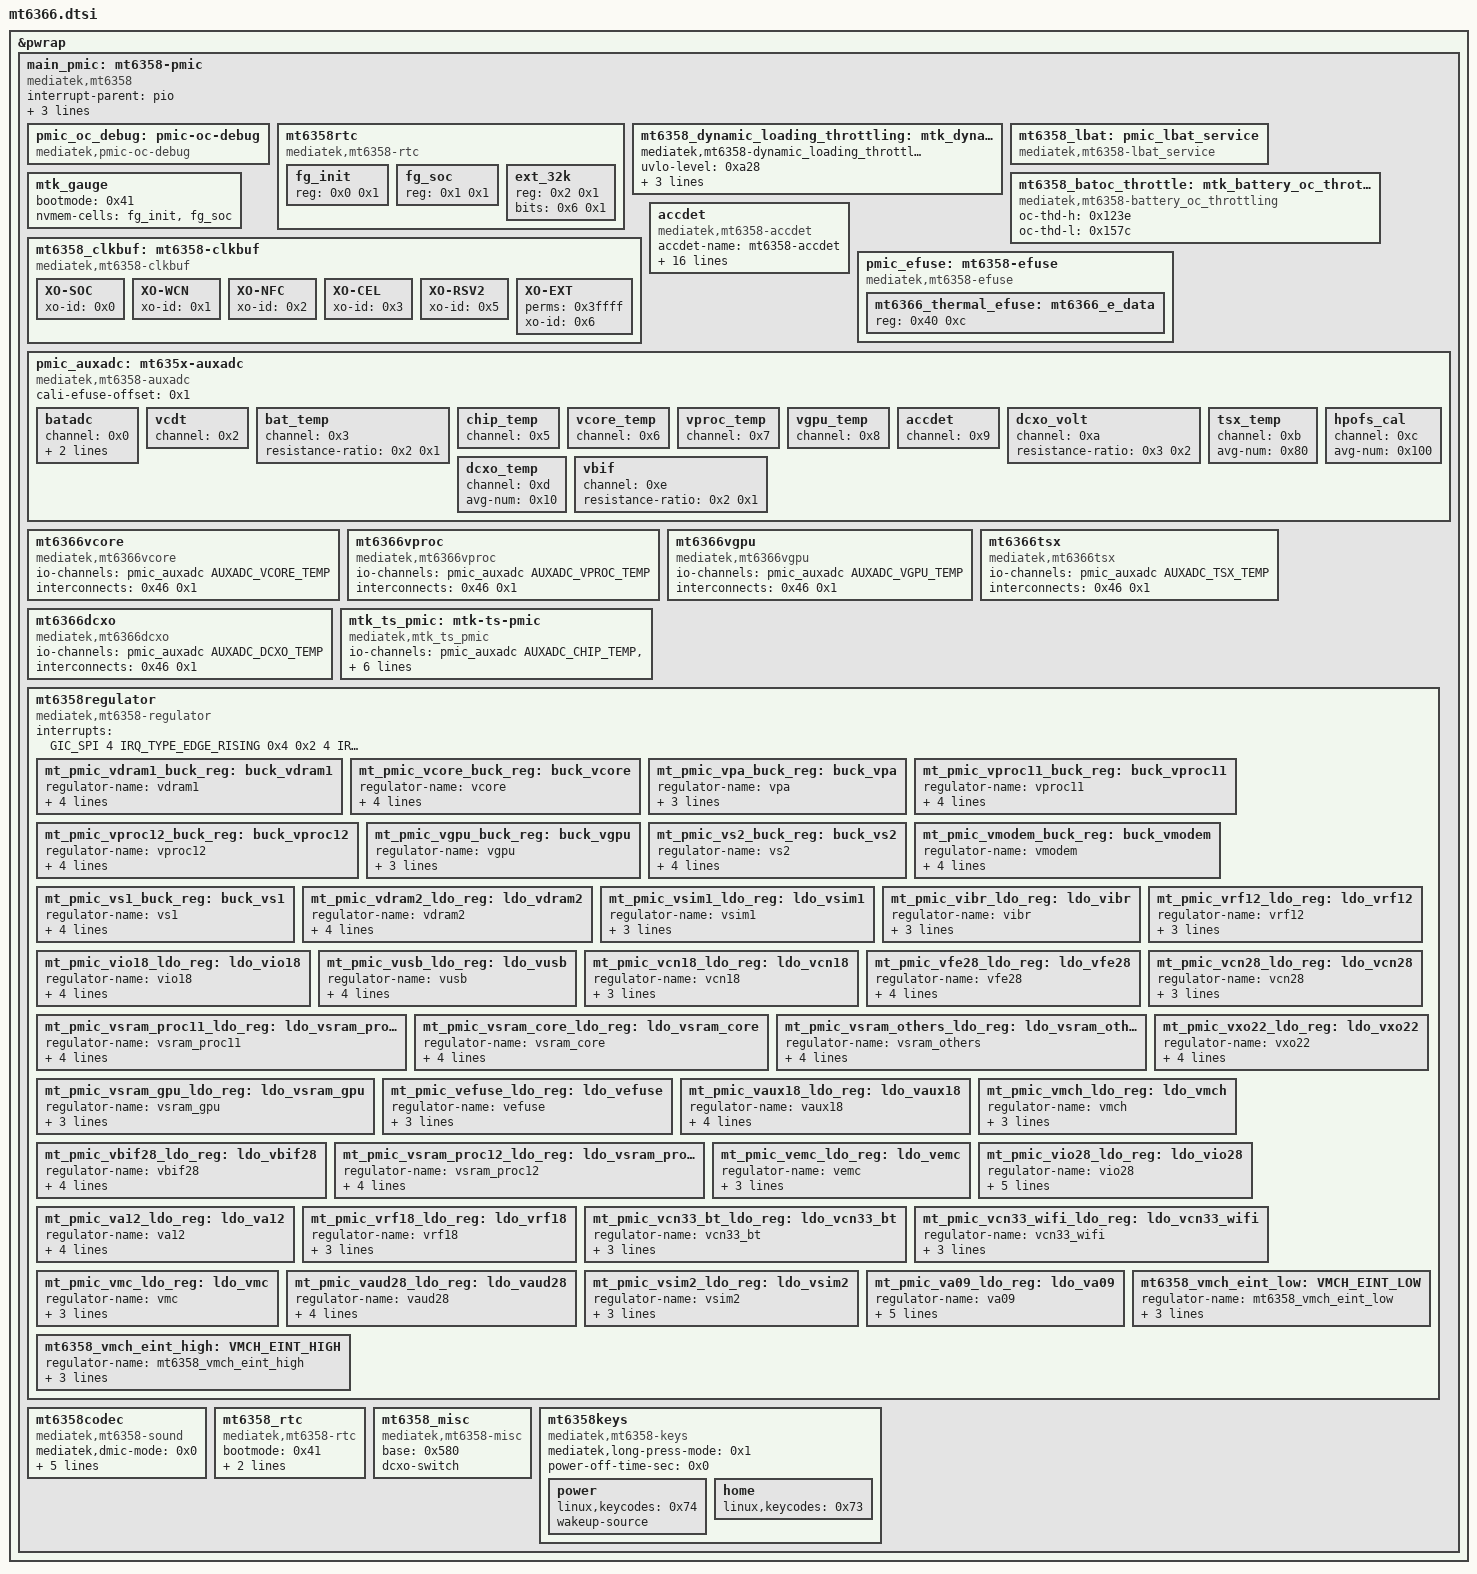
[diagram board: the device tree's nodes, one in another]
// SPDX-License-Identifier: GPL-2.0-only
/* MediaTek MT6358 / MT6366 PMIC MFD, Regulators, AuxADC, RTC, Keys & Gauge bindings for Kernel 6.6 */

&pwrap {
    main_pmic: mt6358-pmic {
        compatible = "mediatek,mt6358";
        interrupt-parent = <&pio>;
        interrupts = <0x90 0x4 0x90 0x0>;
        status = "okay";
        interrupt-controller;
        #interrupt-cells = <0x2>;
        mediatek,num-pmic-irqs = <0x91>;
        pmic_oc_debug: pmic-oc-debug {
            compatible = "mediatek,pmic-oc-debug";
        };
        mt6358rtc: mt6358rtc {
            compatible = "mediatek,mt6358-rtc";
            #address-cells = <0x1>;
            #size-cells = <0x1>;
            fg_init: fg_init {
                reg = <0x0 0x1>;
            };
            fg_soc: fg_soc {
                reg = <0x1 0x1>;
            };
            ext_32k: ext_32k {
                reg = <0x2 0x1>;
                bits = <0x6 0x1>;
            };
        };
        mt6358_dynamic_loading_throttling: mtk_dynamic_loading_throttling {
            compatible = "mediatek,mt6358-dynamic_loading_throttling";
            uvlo-level = <0xa28>;
            io-channels = <&pmic_auxadc AUXADC_IMP &pmic_auxadc AUXADC_IMIX_R &pmic_auxadc AUXADC_BATADC>;
            io-channel-names = "pmic_ptim", "pmic_imix_r", "pmic_batadc";
        };
        mt6358_lbat: pmic_lbat_service {
            compatible = "mediatek,mt6358-lbat_service";
        };
        mt6358_batoc_throttle: mtk_battery_oc_throttling {
            compatible = "mediatek,mt6358-battery_oc_throttling";
            oc-thd-h = <0x123e>;
            oc-thd-l = <0x157c>;
        };
        mtk_gauge: mtk_gauge {
            bootmode = <0x41>;
            nvmem-cells = <&fg_init &fg_soc>;
        };
        mt6358_clkbuf: mt6358-clkbuf {
            compatible = "mediatek,mt6358-clkbuf";
            XO-SOC {
                xo-id = <0x0>;
            };
            XO-WCN {
                xo-id = <0x1>;
            };
            XO-NFC {
                xo-id = <0x2>;
            };
            XO-CEL {
                xo-id = <0x3>;
            };
            XO-RSV2 {
                xo-id = <0x5>;
            };
            XO-EXT {
                perms = <0x3ffff>;
                xo-id = <0x6>;
            };
        };
        accdet: accdet {
            compatible = "mediatek,mt6358-accdet";
            accdet-name = "mt6358-accdet";
            mediatek,accdet-pmic = <0x66>;
            accdet-mic-vol = <0x6>;
            headset-mode-setting = <0x500 0x500 0x1 0x1f0 0x800 0x800 0x20 0x44 0x0 0x0 0xe 0x0 0x0 0x0 0x0>;
            accdet-plugout-debounce = <0x1>;
            accdet-mic-mode = <0x1>;
            headset-eint-level-pol = <0x8>;
            headset-three-key-threshold = <0x0 0x50 0xdc 0x190>;
            headset-three-key-threshold-CDD = <0x0 0x79 0xc0 0x258>;
            headset-four-key-threshold = <0x0 0x3a 0x79 0xc0 0x190>;
            io-channels = <&pmic_auxadc AUXADC_ACCDET>;
            io-channel-names = "pmic_accdet";
            nvmem = <&pmic_efuse>;
            nvmem-names = "mt63xx-accdet-efuse";
            status = "okay";
        };
        pmic_efuse: mt6358-efuse {
            compatible = "mediatek,mt6358-efuse";
            #address-cells = <0x1>;
            #size-cells = <0x1>;
            mt6366_thermal_efuse: mt6366_e_data {
                reg = <0x40 0xc>;
            };
        };
        pmic_auxadc: mt635x-auxadc {
            compatible = "mediatek,mt6358-auxadc";
            #io-channel-cells = <0x1>;
            cali-efuse-offset = <0x1>;
            batadc {
                channel = <0x0>;
                resistance-ratio = <0x3 0x1>;
                avg-num = <0x80>;
            };
            vcdt {
                channel = <0x2>;
            };
            bat_temp {
                channel = <0x3>;
                resistance-ratio = <0x2 0x1>;
            };
            chip_temp {
                channel = <0x5>;
            };
            vcore_temp {
                channel = <0x6>;
            };
            vproc_temp {
                channel = <0x7>;
            };
            vgpu_temp {
                channel = <0x8>;
            };
            accdet {
                channel = <0x9>;
            };
            dcxo_volt {
                channel = <0xa>;
                resistance-ratio = <0x3 0x2>;
            };
            tsx_temp {
                channel = <0xb>;
                avg-num = <0x80>;
            };
            hpofs_cal {
                channel = <0xc>;
                avg-num = <0x100>;
            };
            dcxo_temp {
                channel = <0xd>;
                avg-num = <0x10>;
            };
            vbif {
                channel = <0xe>;
                resistance-ratio = <0x2 0x1>;
            };
        };
        mt6366vcore: mt6366vcore {
            compatible = "mediatek,mt6366vcore";
            io-channels = <&pmic_auxadc AUXADC_VCORE_TEMP>;
            io-channel-names = "pmic_buck1_temp";
            interconnects = <0x46 0x1>;
        };
        mt6366vproc: mt6366vproc {
            compatible = "mediatek,mt6366vproc";
            io-channels = <&pmic_auxadc AUXADC_VPROC_TEMP>;
            io-channel-names = "pmic_buck2_temp";
            interconnects = <0x46 0x1>;
        };
        mt6366vgpu: mt6366vgpu {
            compatible = "mediatek,mt6366vgpu";
            io-channels = <&pmic_auxadc AUXADC_VGPU_TEMP>;
            io-channel-names = "pmic_buck3_temp";
            interconnects = <0x46 0x1>;
        };
        mt6366tsx: mt6366tsx {
            compatible = "mediatek,mt6366tsx";
            io-channels = <&pmic_auxadc AUXADC_TSX_TEMP>;
            io-channel-names = "pmic_tsx_temp";
            interconnects = <0x46 0x1>;
        };
        mt6366dcxo: mt6366dcxo {
            compatible = "mediatek,mt6366dcxo";
            io-channels = <&pmic_auxadc AUXADC_DCXO_TEMP>;
            io-channel-names = "pmic_dcxo_temp";
            interconnects = <0x46 0x1>;
        };
        mtk_ts_pmic: mtk-ts-pmic {
            compatible = "mediatek,mtk_ts_pmic";
            io-channels = <&pmic_auxadc AUXADC_CHIP_TEMP &pmic_auxadc AUXADC_VCORE_TEMP &pmic_auxadc AUXADC_VPROC_TEMP &pmic_auxadc AUXADC_VGPU_TEMP &pmic_auxadc AUXADC_TSX_TEMP &pmic_auxadc AUXADC_DCXO_TEMP>;
            io-channel-names = "pmic_chip_temp", "pmic_buck1_temp", "pmic_buck2_temp", "pmic_buck3_temp", "pmic_tsx_temp", "pmic_dcxo_temp";
            interconnects = <0x40 0x1>;
            #interconnect-cells = <0x1>;
        };
        mt6358regulator: mt6358regulator {
            compatible = "mediatek,mt6358-regulator";
            interrupts = <GIC_SPI 4 IRQ_TYPE_EDGE_RISING 0x4 0x2 4 IRQ_TYPE_EDGE_BOTH 0x4 0x4 4 0x5 0x4 0x6 4 0x7 0x4 0x8 4 0x10 0x4 0x11 4 0x12 0x4 0x13 4 0x14 0x4 0x15 4 0x16 0x4 0x17 4 0x18 0x4 0x19 4 0x1a 0x4 0x1d 4 0x1e 0x4 0x1f 4 0x20 0x4 0x21 4 0x22 0x4 0x23 4 0x24 0x4 0x25 4 0x26 0x4 0x27 4 0x28 0x4 0x29 4 0x2a 0x4 0x2b 4 0x2c 0x4 0x2d 4 0x2e 0x4>;
            interrupt-names = "VPROC11", "VPROC12", "VCORE", "VGPU", "VMODEM", "VDRAM1", "VS1", "VS2", "VPA", "VFE28", "VXO22", "VRF18", "VRF12", "VEFUSE", "VCN33_BT", "VCN28", "VCN18", "VM18", "VMDDR", "VSRAM_CORE", "VA12", "VAUX18", "VAUD28", "VIO28", "VIO18", "VSRAM_PROC11", "VSRAM_PROC12", "VSRAM_OTHERS", "VSRAM_GPU", "VDRAM2", "VMC", "VMCH", "VEMC", "VSIM1", "VSIM2", "VIBR", "VUSB", "VBIF28";
            mt_pmic_vdram1_buck_reg: buck_vdram1 {
                regulator-name = "vdram1";
                regulator-min-microvolt = <0x7a120>;
                regulator-max-microvolt = <0x1fda4c>;
                regulator-enable-ramp-delay = <0x0>;
                regulator-always-on;
            };
            mt_pmic_vcore_buck_reg: buck_vcore {
                regulator-name = "vcore";
                regulator-min-microvolt = <0x7a120>;
                regulator-max-microvolt = <0x13bdb6>;
                regulator-enable-ramp-delay = <0xc8>;
                regulator-always-on;
            };
            mt_pmic_vpa_buck_reg: buck_vpa {
                regulator-name = "vpa";
                regulator-min-microvolt = <0x7a120>;
                regulator-max-microvolt = <0x37b1d0>;
                regulator-enable-ramp-delay = <0xfa>;
            };
            mt_pmic_vproc11_buck_reg: buck_vproc11 {
                regulator-name = "vproc11";
                regulator-min-microvolt = <0x7a120>;
                regulator-max-microvolt = <0x13bdb6>;
                regulator-enable-ramp-delay = <0xc8>;
                regulator-always-on;
            };
            mt_pmic_vproc12_buck_reg: buck_vproc12 {
                regulator-name = "vproc12";
                regulator-min-microvolt = <0x7a120>;
                regulator-max-microvolt = <0x13bdb6>;
                regulator-enable-ramp-delay = <0xc8>;
                regulator-always-on;
            };
            mt_pmic_vgpu_buck_reg: buck_vgpu {
                regulator-name = "vgpu";
                regulator-min-microvolt = <0x7a120>;
                regulator-max-microvolt = <0x13bdb6>;
                regulator-enable-ramp-delay = <0xc8>;
            };
            mt_pmic_vs2_buck_reg: buck_vs2 {
                regulator-name = "vs2";
                regulator-min-microvolt = <0x7a120>;
                regulator-max-microvolt = <0x1fda4c>;
                regulator-enable-ramp-delay = <0x0>;
                regulator-always-on;
            };
            mt_pmic_vmodem_buck_reg: buck_vmodem {
                regulator-name = "vmodem";
                regulator-min-microvolt = <0x7a120>;
                regulator-max-microvolt = <0x13bdb6>;
                regulator-enable-ramp-delay = <0x384>;
                regulator-always-on;
            };
            mt_pmic_vs1_buck_reg: buck_vs1 {
                regulator-name = "vs1";
                regulator-min-microvolt = <0xf4240>;
                regulator-max-microvolt = <0x277b6c>;
                regulator-enable-ramp-delay = <0x0>;
                regulator-always-on;
            };
            mt_pmic_vdram2_ldo_reg: ldo_vdram2 {
                regulator-name = "vdram2";
                regulator-min-microvolt = <0x927c0>;
                regulator-max-microvolt = <0x1b7740>;
                regulator-enable-ramp-delay = <0xce4>;
                regulator-always-on;
            };
            mt_pmic_vsim1_ldo_reg: ldo_vsim1 {
                regulator-name = "vsim1";
                regulator-min-microvolt = <0x19f0a0>;
                regulator-max-microvolt = <0x2f4d60>;
                regulator-enable-ramp-delay = <0x21c>;
            };
            mt_pmic_vibr_ldo_reg: ldo_vibr {
                regulator-name = "vibr";
                regulator-min-microvolt = <0x124f80>;
                regulator-max-microvolt = <0x325aa0>;
                regulator-enable-ramp-delay = <0x3c>;
            };
            mt_pmic_vrf12_ldo_reg: ldo_vrf12 {
                regulator-name = "vrf12";
                regulator-min-microvolt = <0x124f80>;
                regulator-max-microvolt = <0x124f80>;
                regulator-enable-ramp-delay = <0x78>;
            };
            mt_pmic_vio18_ldo_reg: ldo_vio18 {
                regulator-name = "vio18";
                regulator-min-microvolt = <0x1b7740>;
                regulator-max-microvolt = <0x1b7740>;
                regulator-enable-ramp-delay = <0xa8c>;
                regulator-always-on;
            };
            mt_pmic_vusb_ldo_reg: ldo_vusb {
                regulator-name = "vusb";
                regulator-min-microvolt = <0x2dc6c0>;
                regulator-max-microvolt = <0x2f4d60>;
                regulator-enable-ramp-delay = <0x10e>;
                regulator-always-on;
            };
            mt_pmic_vcn18_ldo_reg: ldo_vcn18 {
                regulator-name = "vcn18";
                regulator-min-microvolt = <0x1b7740>;
                regulator-max-microvolt = <0x1b7740>;
                regulator-enable-ramp-delay = <0x10e>;
            };
            mt_pmic_vfe28_ldo_reg: ldo_vfe28 {
                regulator-name = "vfe28";
                regulator-min-microvolt = <0x2ab980>;
                regulator-max-microvolt = <0x2ab980>;
                regulator-enable-ramp-delay = <0x10e>;
                regulator-always-on;
            };
            mt_pmic_vsram_proc11_ldo_reg: ldo_vsram_proc11 {
                regulator-name = "vsram_proc11";
                regulator-min-microvolt = <0x7a120>;
                regulator-max-microvolt = <0x13bdb6>;
                regulator-enable-ramp-delay = <0xf0>;
                regulator-always-on;
            };
            mt_pmic_vcn28_ldo_reg: ldo_vcn28 {
                regulator-name = "vcn28";
                regulator-min-microvolt = <0x2ab980>;
                regulator-max-microvolt = <0x2ab980>;
                regulator-enable-ramp-delay = <0x10e>;
            };
            mt_pmic_vsram_core_ldo_reg: ldo_vsram_core {
                regulator-name = "vsram_core";
                regulator-min-microvolt = <0x7a120>;
                regulator-max-microvolt = <0x13bdb6>;
                regulator-enable-ramp-delay = <0xf0>;
                regulator-always-on;
            };
            mt_pmic_vsram_others_ldo_reg: ldo_vsram_others {
                regulator-name = "vsram_others";
                regulator-min-microvolt = <0x7a120>;
                regulator-max-microvolt = <0x13bdb6>;
                regulator-enable-ramp-delay = <0xf0>;
                regulator-always-on;
            };
            mt_pmic_vsram_gpu_ldo_reg: ldo_vsram_gpu {
                regulator-name = "vsram_gpu";
                regulator-min-microvolt = <0x7a120>;
                regulator-max-microvolt = <0x13bdb6>;
                regulator-enable-ramp-delay = <0xf0>;
            };
            mt_pmic_vxo22_ldo_reg: ldo_vxo22 {
                regulator-name = "vxo22";
                regulator-min-microvolt = <0x2191c0>;
                regulator-max-microvolt = <0x2191c0>;
                regulator-enable-ramp-delay = <0x78>;
                regulator-always-on;
            };
            mt_pmic_vefuse_ldo_reg: ldo_vefuse {
                regulator-name = "vefuse";
                regulator-min-microvolt = <0x19f0a0>;
                regulator-max-microvolt = <0x1cfde0>;
                regulator-enable-ramp-delay = <0x10e>;
            };
            mt_pmic_vaux18_ldo_reg: ldo_vaux18 {
                regulator-name = "vaux18";
                regulator-min-microvolt = <0x1b7740>;
                regulator-max-microvolt = <0x1b7740>;
                regulator-enable-ramp-delay = <0x10e>;
                regulator-always-on;
            };
            mt_pmic_vmch_ldo_reg: ldo_vmch {
                regulator-name = "vmch";
                regulator-min-microvolt = <0x2c4020>;
                regulator-max-microvolt = <0x325aa0>;
                regulator-enable-ramp-delay = <0x3c>;
            };
            mt_pmic_vbif28_ldo_reg: ldo_vbif28 {
                regulator-name = "vbif28";
                regulator-min-microvolt = <0x2ab980>;
                regulator-max-microvolt = <0x2ab980>;
                regulator-enable-ramp-delay = <0x10e>;
                regulator-always-on;
            };
            mt_pmic_vsram_proc12_ldo_reg: ldo_vsram_proc12 {
                regulator-name = "vsram_proc12";
                regulator-min-microvolt = <0x7a120>;
                regulator-max-microvolt = <0x13bdb6>;
                regulator-enable-ramp-delay = <0xf0>;
                regulator-always-on;
            };
            mt_pmic_vemc_ldo_reg: ldo_vemc {
                regulator-name = "vemc";
                regulator-min-microvolt = <0x2c4020>;
                regulator-max-microvolt = <0x325aa0>;
                regulator-enable-ramp-delay = <0x3c>;
            };
            mt_pmic_vio28_ldo_reg: ldo_vio28 {
                regulator-name = "vio28";
                regulator-min-microvolt = <0x2ab980>;
                regulator-max-microvolt = <0x2ab980>;
                regulator-enable-ramp-delay = <0x10e>;
                regulator-always-on;
                regulator-boot-no;
            };
            mt_pmic_va12_ldo_reg: ldo_va12 {
                regulator-name = "va12";
                regulator-min-microvolt = <0x124f80>;
                regulator-max-microvolt = <0x124f80>;
                regulator-enable-ramp-delay = <0x10e>;
                regulator-always-on;
            };
            mt_pmic_vrf18_ldo_reg: ldo_vrf18 {
                regulator-name = "vrf18";
                regulator-min-microvolt = <0x1b7740>;
                regulator-max-microvolt = <0x1b7740>;
                regulator-enable-ramp-delay = <0x78>;
            };
            mt_pmic_vcn33_bt_ldo_reg: ldo_vcn33_bt {
                regulator-name = "vcn33_bt";
                regulator-min-microvolt = <0x325aa0>;
                regulator-max-microvolt = <0x3567e0>;
                regulator-enable-ramp-delay = <0x10e>;
            };
            mt_pmic_vcn33_wifi_ldo_reg: ldo_vcn33_wifi {
                regulator-name = "vcn33_wifi";
                regulator-min-microvolt = <0x325aa0>;
                regulator-max-microvolt = <0x3567e0>;
                regulator-enable-ramp-delay = <0x10e>;
            };
            mt_pmic_vmc_ldo_reg: ldo_vmc {
                regulator-name = "vmc";
                regulator-min-microvolt = <0x1b7740>;
                regulator-max-microvolt = <0x325aa0>;
                regulator-enable-ramp-delay = <0x3c>;
            };
            mt_pmic_vaud28_ldo_reg: ldo_vaud28 {
                regulator-name = "vaud28";
                regulator-min-microvolt = <0x2ab980>;
                regulator-max-microvolt = <0x2ab980>;
                regulator-enable-ramp-delay = <0x10e>;
                regulator-always-on;
            };
            mt_pmic_vsim2_ldo_reg: ldo_vsim2 {
                regulator-name = "vsim2";
                regulator-min-microvolt = <0x19f0a0>;
                regulator-max-microvolt = <0x2f4d60>;
                regulator-enable-ramp-delay = <0x21c>;
            };
            mt_pmic_va09_ldo_reg: ldo_va09 {
                regulator-name = "va09";
                regulator-min-microvolt = <0xdbba0>;
                regulator-max-microvolt = <0xdbba0>;
                regulator-enable-ramp-delay = <0x108>;
                regulator-boot-on;
                regulator-always-on;
            };
            mt6358_vmch_eint_high: VMCH_EINT_HIGH {
                regulator-name = "mt6358_vmch_eint_high";
                regulator-min-microvolt = <0x2c4020>;
                regulator-max-microvolt = <0x325aa0>;
                regulator-enable-ramp-delay = <0x3c>;
            };
            mt6358_vmch_eint_low: VMCH_EINT_LOW {
                regulator-name = "mt6358_vmch_eint_low";
                regulator-min-microvolt = <0x2c4020>;
                regulator-max-microvolt = <0x325aa0>;
                regulator-enable-ramp-delay = <0x3c>;
            };
        };
        mt6358codec: mt6358codec {
            compatible = "mediatek,mt6358-sound";
            mediatek,dmic-mode = <0x0>;
            mediatek,mic-type = <0x1>;
            io-channels = <&pmic_auxadc AUXADC_HPOFS_CAL>;
            io-channel-names = "pmic_hpofs_cal";
            nvmem = <&pmic_efuse>;
            nvmem-names = "pmic-hp-efuse";
            reg-vaud28-supply = <&mt_pmic_vaud28_ldo_reg>;
        };
        mt6358_rtc: mt6358_rtc {
            compatible = "mediatek,mt6358-rtc";
            bootmode = <0x41>;
            interrupts = <0x40 0x0>;
            interrupt-names = "rtc";
            base = <0x580>;
        };
        mt6358_misc: mt6358_misc {
            compatible = "mediatek,mt6358-misc";
            base = <0x580>;
            dcxo-switch;
        };
        mt6358keys: mt6358keys {
            compatible = "mediatek,mt6358-keys";
            mediatek,long-press-mode = <0x1>;
            power-off-time-sec = <0x0>;
            power {
                linux,keycodes = <0x74>;
                wakeup-source;
            };
            home {
                linux,keycodes = <0x73>;
            };
        };
    };
};

#include "bat_setting/mt6781_battery_prop_dim2_ext.dtsi"
